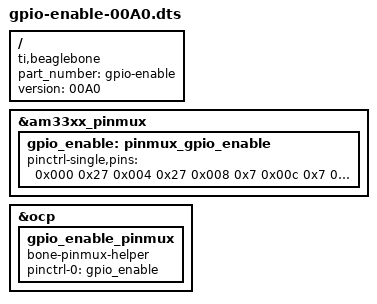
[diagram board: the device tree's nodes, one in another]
/dts-v1/;
/plugin/;

/{
	compatible = "ti,beaglebone", "ti,beaglebone-black";
	part_number = "gpio-enable";
	version = "00A0";

	fragment@0 {
		target = <&am33xx_pinmux>;

		__overlay__ {
			gpio_enable: pinmux_gpio_enable {
				pinctrl-single,pins = <	0x000 0x27
							0x004 0x27
							0x008 0x7
							0x00c 0x7
							0x010 0x7
							0x014 0x7
							0x018 0x7
							0x01c 0x7
							0x030 0x27
							0x034 0x7
							0x038 0x7
							0x03c 0x7
							0x08c 0x7
							0x090 0x7
							0x094 0x7
							0x098 0x7
							0x09c 0x7
							0x0c0 0x27
							0x164 0x27
							0x0d0 0x27
							0x0d4 0x27
							0x0d8 0x7
							0x0dc 0x27
							0x178 0x7
							0x17c 0x27
							0x180 0x27
							0x184 0x27
							0x1b4 0x27
							0x020 0x27
							0x024 0x27
							0x028 0x27
							0x040 0x7
							0x044 0x27
							0x048 0x27
							0x04c 0x27
							0x078 0x27
							0x07c 0x27
							0x084 0x7
							0x0c4 0x27
							0x0c8 0x27
							0x0cc 0x27
							0x0ec 0x27
							0x02c 0x7
							0x070 0x27
							0x074 0x7
				>;
			};
		};
	};

	fragment@1 {
                target = <&ocp>;

                __overlay__ {
                        gpio_enable_pinmux {
                                compatible = "bone-pinmux-helper";
                                status = "okay";
                                pinctrl-names = "default";
                                pinctrl-0 = <&gpio_enable>;
                        };
                };
        };

};
